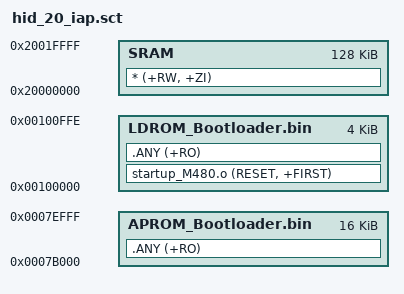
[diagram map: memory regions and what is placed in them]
LOAD_ROM_1  0x100000 0xFFF
{
	LDROM_Bootloader.bin  0x100000 0xFFF
	{
		startup_M480.o (RESET, +FIRST)
        .ANY (+RO)
	}
	
	SRAM  0x20000000 0x20000
	{
		* (+RW, +ZI)
	}
}

LOAD_ROM_2  0x7B000 0x4000
{
	APROM_Bootloader.bin  0x7B000 0x4000
	{
        .ANY (+RO)
	}
}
